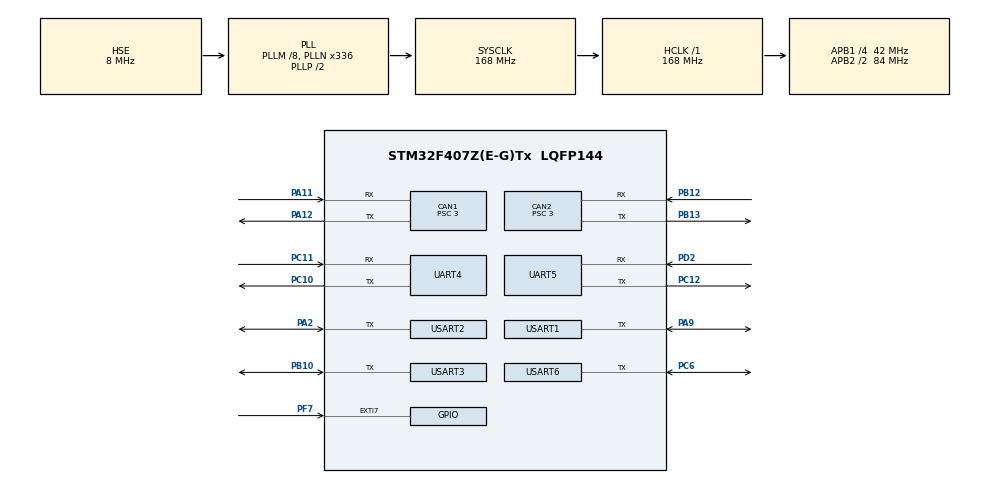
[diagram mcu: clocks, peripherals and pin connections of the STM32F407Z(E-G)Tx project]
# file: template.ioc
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CAN1.ABOM=ENABLE
CAN1.BS1=CAN_BS1_9TQ
CAN1.BS2=CAN_BS2_4TQ
CAN1.CalculateBaudRate=1000000
CAN1.CalculateTimeBit=1000
CAN1.CalculateTimeQuantum=71.42857142857143
CAN1.NART=DISABLE
CAN1.Prescaler=3
CAN2.ABOM=ENABLE
CAN2.BS1=CAN_BS1_12TQ
CAN2.BS2=CAN_BS2_8TQ
CAN2.CalculateBaudRate=666666
CAN2.CalculateTimeBit=1500
CAN2.CalculateTimeQuantum=71.42857142857143
CAN2.NART=DISABLE
CAN2.Prescaler=3
FREERTOS.Tasks01=defaultTask,24,128,StartDefaultTask,Default,NULL,Dynamic,NULL,NULL;move_base_task,24,128,move_base,Default,NULL,Dynamic,NULL,NULL;Robot_state_tas,25,128,Robot_state,Default,NULL,Dynamic,NULL,NULL;Auto_task,26,128,Auto,Default,NULL,Dynamic,NULL,NULL;data_update_tas,48,128,data_update,Default,NULL,Dynamic,NULL,NULL;motor_control_t,49,128,motor_control,Default,NULL,Dynamic,NULL,NULL
Mcu.Family=STM32F4
Mcu.Name=STM32F407Z(E-G)Tx
Mcu.Package=LQFP144
NVIC.CAN1_RX0_IRQn=true\:2\:0\:true\:false\:true\:false\:true\:true\:true
NVIC.CAN1_RX1_IRQn=true\:2\:0\:true\:false\:true\:false\:true\:true\:true
NVIC.CAN1_SCE_IRQn=true\:2\:0\:true\:false\:true\:false\:true\:true\:true
NVIC.CAN1_TX_IRQn=true\:2\:0\:true\:false\:true\:false\:true\:true\:true
NVIC.CAN2_RX0_IRQn=true\:5\:0\:false\:false\:true\:true\:true\:true\:true
NVIC.CAN2_RX1_IRQn=true\:5\:0\:false\:false\:true\:true\:true\:true\:true
NVIC.CAN2_SCE_IRQn=true\:5\:0\:false\:false\:true\:true\:true\:true\:true
NVIC.CAN2_TX_IRQn=true\:5\:0\:false\:false\:true\:true\:true\:true\:true
NVIC.EXTI9_5_IRQn=true\:2\:0\:true\:false\:true\:false\:true\:true\:true
NVIC.PriorityGroup=NVIC_PRIORITYGROUP_4
NVIC.TIM2_IRQn=true\:5\:0\:false\:false\:true\:true\:true\:true\:true
NVIC.UART4_IRQn=true\:5\:0\:false\:false\:true\:true\:true\:true\:true
NVIC.USART1_IRQn=true\:5\:0\:false\:false\:true\:true\:true\:true\:true
PA11.Mode=CAN_Activate
PA11.Signal=CAN1_RX
PA12.Mode=CAN_Activate
PA12.Signal=CAN1_TX
PA13.Mode=Serial_Wire
PA13.Signal=SYS_JTMS-SWDIO
PA14.Mode=Serial_Wire
PA14.Signal=SYS_JTCK-SWCLK
PA2.Mode=Half_duplex(single_wire_mode)
PA2.Signal=USART2_TX
PA9.Mode=Half_duplex(single_wire_mode)
PA9.Signal=USART1_TX
PB10.Mode=Half_duplex(single_wire_mode)
PB10.Signal=USART3_TX
PB12.Mode=CAN_Activate
PB12.Signal=CAN2_RX
PB13.Mode=CAN_Activate
PB13.Signal=CAN2_TX
PC10.Mode=Asynchronous
PC10.Signal=UART4_TX
PC11.Mode=Asynchronous
PC11.Signal=UART4_RX
PC12.Mode=Asynchronous
PC12.Signal=UART5_TX
PC14-OSC32_IN.Mode=LSE-External-Oscillator
PC14-OSC32_IN.Signal=RCC_OSC32_IN
PC15-OSC32_OUT.Mode=LSE-External-Oscillator
PC15-OSC32_OUT.Signal=RCC_OSC32_OUT
PC6.Mode=Half_duplex(single_wire_mode)
PC6.Signal=USART6_TX
PD2.Mode=Asynchronous
PD2.Signal=UART5_RX
PF7.GPIO_PuPd=GPIO_NOPULL
PF7.Signal=GPXTI7
PH0-OSC_IN.Mode=HSE-External-Oscillator
PH0-OSC_IN.Signal=RCC_OSC_IN
PH1-OSC_OUT.Mode=HSE-External-Oscillator
PH1-OSC_OUT.Signal=RCC_OSC_OUT
ProjectManager.HeapSize=0x200
ProjectManager.StackSize=0x400
ProjectManager.TargetToolchain=MDK-ARM V5.27
RCC.48MHZClocksFreq_Value=84000000
RCC.AHBFreq_Value=168000000
RCC.APB1CLKDivider=RCC_HCLK_DIV4
RCC.APB1Freq_Value=42000000
RCC.APB1TimFreq_Value=84000000
RCC.APB2CLKDivider=RCC_HCLK_DIV2
RCC.APB2Freq_Value=84000000
RCC.APB2TimFreq_Value=168000000
RCC.CortexFreq_Value=168000000
RCC.HCLKFreq_Value=168000000
RCC.HSE_VALUE=8000000
RCC.HSI_VALUE=16000000
RCC.PLLM=8
RCC.PLLN=336
RCC.PLLSourceVirtual=RCC_PLLSOURCE_HSE
RCC.SYSCLKFreq_VALUE=168000000
RCC.SYSCLKSource=RCC_SYSCLKSOURCE_PLLCLK
RCC.VCOOutputFreq_Value=336000000
STMicroelectronics.X-CUBE-ALGOBUILD.1.3.0.LibraryCcDSPOoLibraryJjDSPOoLibrary=true
TIM2.AutoReloadPreload=TIM_AUTORELOAD_PRELOAD_ENABLE
TIM2.Period=10000
TIM2.Prescaler=83
UART4.VirtualMode=Asynchronous
UART5.VirtualMode=Asynchronous
USART1.VirtualMode=VM_ASYNC
USART2.VirtualMode=VM_ASYNC
USART3.VirtualMode=VM_ASYNC
USART6.VirtualMode=VM_ASYNC
VP_FREERTOS_VS_CMSIS_V2.Mode=CMSIS_V2
VP_STMicroelectronics.X-CUBE-ALGOBUILD_VS_DSPOoLibraryJjLibrary_1.3.0_1.3.0.Mode=DSPOoLibraryJjLibrary
VP_TIM2_VS_ClockSourceINT.Mode=Internal
board=custom

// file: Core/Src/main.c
/* USER CODE BEGIN Header */
//下面的注释一个都不要删，防止重新配置导致代码缺失
/**
  ******************************************************************************
  * @file           : main.c
  * @brief          : Main program body
  ******************************************************************************
  * @attention
  *
  * <h2><center>&copy; Copyright (c) 2023 STMicroelectronics.
  * All rights reserved.</center></h2>
  *
  * This software component is licensed by ST under Ultimate Liberty license
  * SLA0044, the "License"; You may not use this file except in compliance with
  * the License. You may obtain a copy of the License at:
  *                             www.st.com/SLA0044
  *
  ******************************************************************************
  */
/* USER CODE END Header */
#include "main.h"
#include "cmsis_os.h"
#include "can.h"
#include "tim.h"
#include "usart.h"
#include "gpio.h"

/* USER CODE BEGIN Includes */
#include "moto.h"
/* USER CODE END Includes */

void SystemClock_Config(void);
void MX_FREERTOS_Init(void);

int main(void)
{

  /* MCU Configuration--------------------------------------------------------*/

  /* Reset of all peripherals, Initializes the Flash interface and the Systick. */
  HAL_Init();

  /* Configure the system clock */
  SystemClock_Config();

  /* Initialize all configured peripherals */
  MX_GPIO_Init();
  MX_CAN1_Init();
  MX_CAN2_Init();
  MX_UART4_Init();
  MX_UART5_Init();
  MX_USART1_UART_Init();
  MX_USART2_UART_Init();
  MX_USART3_UART_Init();
  MX_USART6_UART_Init();
  MX_TIM2_Init();
  /* USER CODE BEGIN 2 */

	HAL_TIM_Base_Start_IT(&htim2);
	HAL_CAN_Start(&hcan1);
//	MotorInit();
  /* USER CODE END 2 */

  /* Init scheduler */
  osKernelInitialize();  /* Call init function for freertos objects (in freertos.c) */
  MX_FREERTOS_Init();
  /* Start scheduler */
  osKernelStart();

  /* We should never get here as control is now taken by the scheduler */
  /* Infinite loop */
  while (1)
  {

  }
}

void SystemClock_Config(void)
{
  RCC_OscInitTypeDef RCC_OscInitStruct = {0};
  RCC_ClkInitTypeDef RCC_ClkInitStruct = {0};

  /** Configure the main internal regulator output voltage
  */
  __HAL_RCC_PWR_CLK_ENABLE();
  __HAL_PWR_VOLTAGESCALING_CONFIG(PWR_REGULATOR_VOLTAGE_SCALE1);
  /** Initializes the RCC Oscillators according to the specified parameters
  * in the RCC_OscInitTypeDef structure.
  */
  RCC_OscInitStruct.OscillatorType = RCC_OSCILLATORTYPE_HSE;
  RCC_OscInitStruct.HSEState = RCC_HSE_ON;
  RCC_OscInitStruct.PLL.PLLState = RCC_PLL_ON;
  RCC_OscInitStruct.PLL.PLLSource = RCC_PLLSOURCE_HSE;
  RCC_OscInitStruct.PLL.PLLM = 8;
  RCC_OscInitStruct.PLL.PLLN = 336;
  RCC_OscInitStruct.PLL.PLLP = RCC_PLLP_DIV2;
  RCC_OscInitStruct.PLL.PLLQ = 4;
  if (HAL_RCC_OscConfig(&RCC_OscInitStruct) != HAL_OK)
  {
    Error_Handler();
  }
  /** Initializes the CPU, AHB and APB buses clocks
  */
  RCC_ClkInitStruct.ClockType = RCC_CLOCKTYPE_HCLK|RCC_CLOCKTYPE_SYSCLK
                              |RCC_CLOCKTYPE_PCLK1|RCC_CLOCKTYPE_PCLK2;
  RCC_ClkInitStruct.SYSCLKSource = RCC_SYSCLKSOURCE_PLLCLK;
  RCC_ClkInitStruct.AHBCLKDivider = RCC_SYSCLK_DIV1;
  RCC_ClkInitStruct.APB1CLKDivider = RCC_HCLK_DIV4;
  RCC_ClkInitStruct.APB2CLKDivider = RCC_HCLK_DIV2;

  if (HAL_RCC_ClockConfig(&RCC_ClkInitStruct, FLASH_LATENCY_5) != HAL_OK)
  {
    Error_Handler();
  }
}

void Error_Handler(void)
{
  __disable_irq();
  while (1)
  {
  }
}

/************************ (C) COPYRIGHT STMicroelectronics *****END OF FILE****/

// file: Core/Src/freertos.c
/* USER CODE BEGIN Header */
/**
  ******************************************************************************
  * File Name          : freertos.c
  * Description        : Code for freertos applications
  ******************************************************************************
  * @attention
  *
  * <h2><center>&copy; Copyright (c) 2023 STMicroelectronics.
  * All rights reserved.</center></h2>
  *
  * This software component is licensed by ST under Ultimate Liberty license
  * SLA0044, the "License"; You may not use this file except in compliance with
  * the License. You may obtain a copy of the License at:
  *                             www.st.com/SLA0044
  *
  ******************************************************************************
  */
/* USER CODE END Header */

#include "FreeRTOS.h"
#include "task.h"
#include "main.h"
#include "cmsis_os.h"

/* USER CODE BEGIN Includes */
#include "moto.h"
/* USER CODE END Includes */

/* Definitions for defaultTask */
osThreadId_t defaultTaskHandle;
const osThreadAttr_t defaultTask_attributes = {
  .name = "defaultTask",
  .stack_size = 128 * 4,
  .priority = (osPriority_t) osPriorityNormal,
};
/* Definitions for move_base_task */
osThreadId_t move_base_taskHandle;
const osThreadAttr_t move_base_task_attributes = {
  .name = "move_base_task",
  .stack_size = 128 * 4,
  .priority = (osPriority_t) osPriorityNormal,
};
/* Definitions for Robot_state_tas */
osThreadId_t Robot_state_tasHandle;
const osThreadAttr_t Robot_state_tas_attributes = {
  .name = "Robot_state_tas",
  .stack_size = 128 * 4,
  .priority = (osPriority_t) osPriorityNormal1,
};
/* Definitions for Auto_task */
osThreadId_t Auto_taskHandle;
const osThreadAttr_t Auto_task_attributes = {
  .name = "Auto_task",
  .stack_size = 128 * 4,
  .priority = (osPriority_t) osPriorityNormal2,
};
/* Definitions for data_update_tas */
osThreadId_t data_update_tasHandle;
const osThreadAttr_t data_update_tas_attributes = {
  .name = "data_update_tas",
  .stack_size = 128 * 4,
  .priority = (osPriority_t) osPriorityRealtime,
};
/* Definitions for motor_control_t */
osThreadId_t motor_control_tHandle;
const osThreadAttr_t motor_control_t_attributes = {
  .name = "motor_control_t",
  .stack_size = 128 * 4,
  .priority = (osPriority_t) osPriorityRealtime1,
};

void StartDefaultTask(void *argument);
void move_base(void *argument);
void Robot_state(void *argument);
void Auto(void *argument);
void data_update(void *argument);
void motor_control(void *argument);

void MX_FREERTOS_Init(void); /* (MISRA C 2004 rule 8.1) */

void MX_FREERTOS_Init(void) {

  /* Create the thread(s) */
  /* creation of defaultTask */
  defaultTaskHandle = osThreadNew(StartDefaultTask, NULL, &defaultTask_attributes);

  /* creation of move_base_task */
  move_base_taskHandle = osThreadNew(move_base, NULL, &move_base_task_attributes);

  /* creation of Robot_state_tas */
  Robot_state_tasHandle = osThreadNew(Robot_state, NULL, &Robot_state_tas_attributes);

  /* creation of Auto_task */
  Auto_taskHandle = osThreadNew(Auto, NULL, &Auto_task_attributes);

  /* creation of data_update_tas */
  data_update_tasHandle = osThreadNew(data_update, NULL, &data_update_tas_attributes);

  /* creation of motor_control_t */
  motor_control_tHandle = osThreadNew(motor_control, NULL, &motor_control_t_attributes);

}

void StartDefaultTask(void *argument)
{
  /* USER CODE BEGIN StartDefaultTask */
  /* Infinite loop */

  for(;;)
  {
		uint16_t speedtest=0;
		M3508_CHASSIS_MOTOR_REAL_INFO[0].TARGET_CURRENT=speedtest;

    osDelay(1);
  }
  /* USER CODE END StartDefaultTask */
}

void move_base(void *argument)
{
  for(;;)
  {
    osDelay(1);
  }
}

void Robot_state(void *argument)
{
  for(;;)
  {
    osDelay(1);
  }
}

void Auto(void *argument)
{
  for(;;)
  {
    osDelay(1);
  }
}

void data_update(void *argument)
{
  /* USER CODE BEGIN data_update */
  /* Infinite loop */
  for(;;)
  {
		chassis_m3508_send_motor_currents();

    osDelay(5);
  }
  /* USER CODE END data_update */
}

void motor_control(void *argument)
{
  for(;;)
  {
    osDelay(1);
  }
}

/************************ (C) COPYRIGHT STMicroelectronics *****END OF FILE****/
